AUTOSAR XML (schema 00048)
package /SoftwareTypes/ComponentTypes
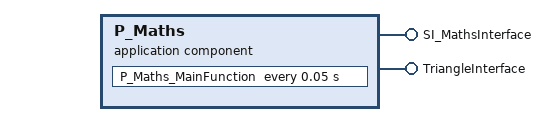
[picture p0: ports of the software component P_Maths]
  application sw component type P_Maths
    provide port SI_MathsInterface: provided-interface=SI_MathsInterface
      provided-com-specs:
        operation=Add, queue-length=1
        operation=Divide, queue-length=1
        operation=Multiply, queue-length=1
        operation=Substract, queue-length=1
    provide port TriangleInterface: nonqueued-sender-com-spec{data-element=Triangle, init-value=fields=0}, provided-interface=TriangleInterface
    behavior P_Maths_ib: data-type-mapping=Data_Type_Mappings
      timing event TMT_P_Maths_MainFunction: start-on-event=P_Maths_MainFunction, period=0.05
      4 x operation invoked event:
        OIT_P_Maths_SI_MathsInterface_Add_SI_MathsInterface_Add: start-on-event=P_Maths_SI_MathsInterface_Add, operation=SI_MathsInterface.Add
        OIT_P_Maths_SI_MathsInterface_Divide_SI_MathsInterface_Divide: start-on-event=P_Maths_SI_MathsInterface_Divide, operation=SI_MathsInterface.Divide
        OIT_P_Maths_SI_MathsInterface_Multiply_SI_MathsInterface_Multiply: start-on-event=P_Maths_SI_MathsInterface_Multiply, operation=SI_MathsInterface.Multiply
        OIT_P_Maths_SI_MathsInterface_Substract_SI_MathsInterface_Substract: start-on-event=P_Maths_SI_MathsInterface_Substract, operation=SI_MathsInterface.Substract
      5 x runnable:
        P_Maths_MainFunction
          data-send-points:
            access SEND_TriangleInterface_Triangle: accessed-variable=TriangleInterface.Triangle
        P_Maths_SI_MathsInterface_Add
        P_Maths_SI_MathsInterface_Divide
        P_Maths_SI_MathsInterface_Multiply
        P_Maths_SI_MathsInterface_Substract
